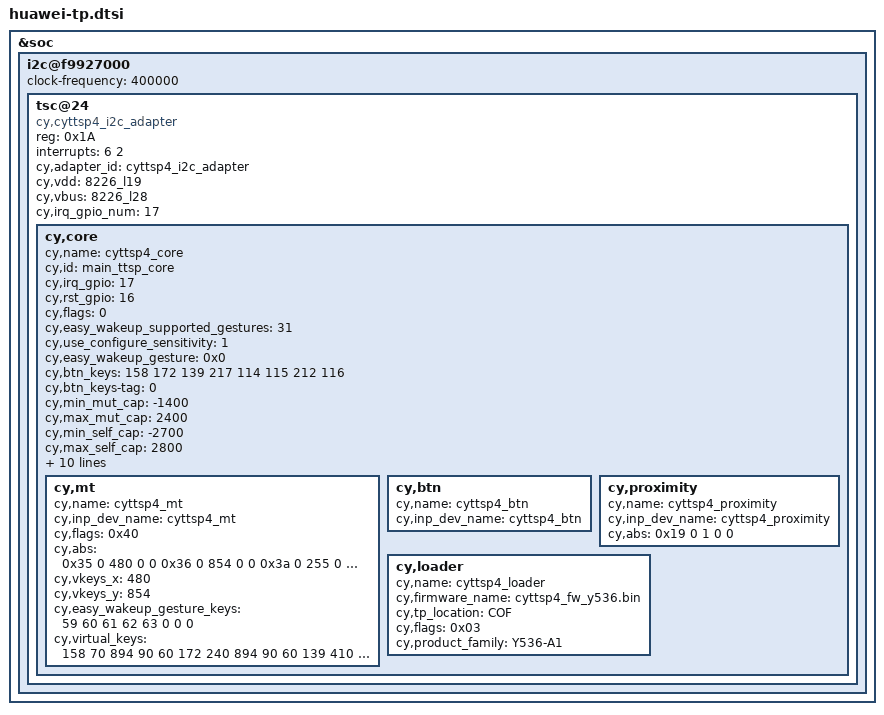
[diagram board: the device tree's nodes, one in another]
&soc {
	/* BLSP1 QUP5 */
	i2c@f9927000 { 
		clock-frequency = <400000>;

		tsc@24 {
			compatible = "cy,cyttsp4_i2c_adapter";
			reg = <0x1A>;
			/* GPIO 17, high-to-low edge triggered */
			interrupts = <6 2>;
			/* interrupt-parent = <&gpio2>; */
			cy,adapter_id = "cyttsp4_i2c_adapter";
			cy,vdd = "8226_l19";
			cy,vbus = "8226_l28";
			cy,irq_gpio_num = <17>;
			cy,core {
				cy,name = "cyttsp4_core";
				cy,id = "main_ttsp_core";

				cy,irq_gpio = <17>;
				cy,rst_gpio = <16>;

				/* Enable cy,max_xfer_len to limit max I2C/SPI transfer length */
				/* cy,max_xfer_len = <0x100>; */

				/* CY_CORE_FLAG_WAKE_ON_GESTURE */
				cy,flags = <0>;
				cy,easy_wakeup_supported_gestures = <31>; /*supported gestures ored bits*/

				/* GLOVE function */
				cy,use_configure_sensitivity = <1>;

				/* CY_CORE_EWG_TAP_TAP | CY_CORE_EWG_TWO_FINGER_SLIDE */
				cy,easy_wakeup_gesture = <0x0>;
				/* This section decide the independence keys' order */
				/* KEY_HOMEPAGE instead of KEY_HOME(102) */
				cy,btn_keys = <158 /* KEY_BACK */
						172 /* KEY_HOME */
						139 /* KEY_MENU */
						217 /* KEY_SEARCH */
						114 /* KEY_VOLUMEDOWN */
						115 /* KEY_VOLUMEUP */
						212 /* KEY_CAMERA */
						116>; /* KEY_POWER */
				cy,btn_keys-tag = <0>;

				/* tp capacitance infomation, add btn value */
				cy,min_mut_cap = "-1400"; /*minimum mutual capcitance*/
				cy,max_mut_cap = "2400"; /*maximum mutual capcitance*/
				cy,min_self_cap = "-2700"; /*minimum self capcitance*/
				cy,max_self_cap = "2800"; /*maximum self capcitance*/
				/* Use threshold suggested by vendor */
				cy,min_btn_mut_cap = "-1200"; /*minimum button mutual capcitance*/
				cy,max_btn_mut_cap = "1200"; /*maximum button mutual capcitance*/
				cy,min_btn_self_cap = "-1700"; /*minimum button self capcitance*/
				cy,max_btn_self_cap = "2200"; /*maximum button self capcitance*/
				cy,tx_lines = <19>; /*number of Tx lines*/
				cy,rx_lines = <11>; /*Number of Rx lines*/
				cy,self_cap_num = <11>; /* Number of self cap lines */
				cy,btn_num = <3>; /*Number of buttons*/
				cy,data_start_byte = <8>; /*the data byte after command header*/
				cy,tp_ic_version = "TMA445D";/*ic version*/

				cy,mt {
					cy,name = "cyttsp4_mt";

					cy,inp_dev_name = "cyttsp4_mt";
					/* CY_MT_FLAG_FLIP | CY_MT_FLAG_INV_X | CY_MT_FLAG_INV_Y */
					cy,flags = <0x40>;
					cy,abs =
						/* ABS_MT_POSITION_X, CY_ABS_MIN_X, CY_ABS_MAX_X, 0, 0 */
						<0x35 0 480 0 0
						/* ABS_MT_POSITION_Y, CY_ABS_MIN_Y, CY_ABS_MAX_Y, 0, 0 */
						0x36 0 854 0 0
						/* ABS_MT_PRESSURE, CY_ABS_MIN_P, CY_ABS_MAX_P, 0, 0 */
						0x3a 0 255 0 0
						/* CY_IGNORE_VALUE, CY_ABS_MIN_W, CY_ABS_MAX_W, 0, 0 */
						0xffff 0 255 0 0
						/* ABS_MT_TRACKING_ID, CY_ABS_MIN_T, CY_ABS_MAX_T, 0, 0 */
						0x39 0 15 0 0
						/* ABS_MT_TOUCH_MAJOR, 0, 255, 0, 0 */
						0x30 0 255 0 0
						/* ABS_MT_TOUCH_MINOR, 0, 255, 0, 0 */
						0x31 0 255 0 0
						/* ABS_MT_ORIENTATION, -128, 127, 0, 0 */
						0x34 0xfffffed7 127 0 0>;

					cy,vkeys_x = <480>;
					cy,vkeys_y = <854>;

					/*8 bits  for gesture control*/
					cy,easy_wakeup_gesture_keys = <	59 /*Double tap*/
						60 /*Single finger slide from left to right*/
						61 /*Single finger slide from right to left*/
						62 /*Single finger slide from top to bottom*/
						63 /*Single finger slide from bottom to top*/
						0  /*Not used*/
						0  /*Not used*/
						0  /*Not used*/
						>;

					/* modify Y to match virtual keys fileds */
					cy,virtual_keys = /* KeyCode CenterX CenterY Width Height */
						/* KEY_BACK */
						<158 70 894 90 60
						/* KEY_HOMEPAGE instead of KEY_HOME(102) */
						172 240 894 90 60
						/* KEY_MENU */
						139 410 894 90 60>;
				};

				cy,btn {
					cy,name = "cyttsp4_btn";

					cy,inp_dev_name = "cyttsp4_btn";
				};

				cy,proximity {
					cy,name = "cyttsp4_proximity";

					cy,inp_dev_name = "cyttsp4_proximity";
					cy,abs =
						/* ABS_DISTANCE, CY_PROXIMITY_MIN_VAL, CY_PROXIMITY_MAX_VAL, 0, 0 */
						<0x19 0 1 0 0>;
				};

				cy,loader {
					cy,name = "cyttsp4_loader";

					cy,firmware_name = "cyttsp4_fw_y536.bin";
					cy,tp_location = "COF";
					/* Force recalibration */
					cy,flags = <0x03>;
					cy,product_family = "Y536-A1";
				};
			};
		};
	};

};
